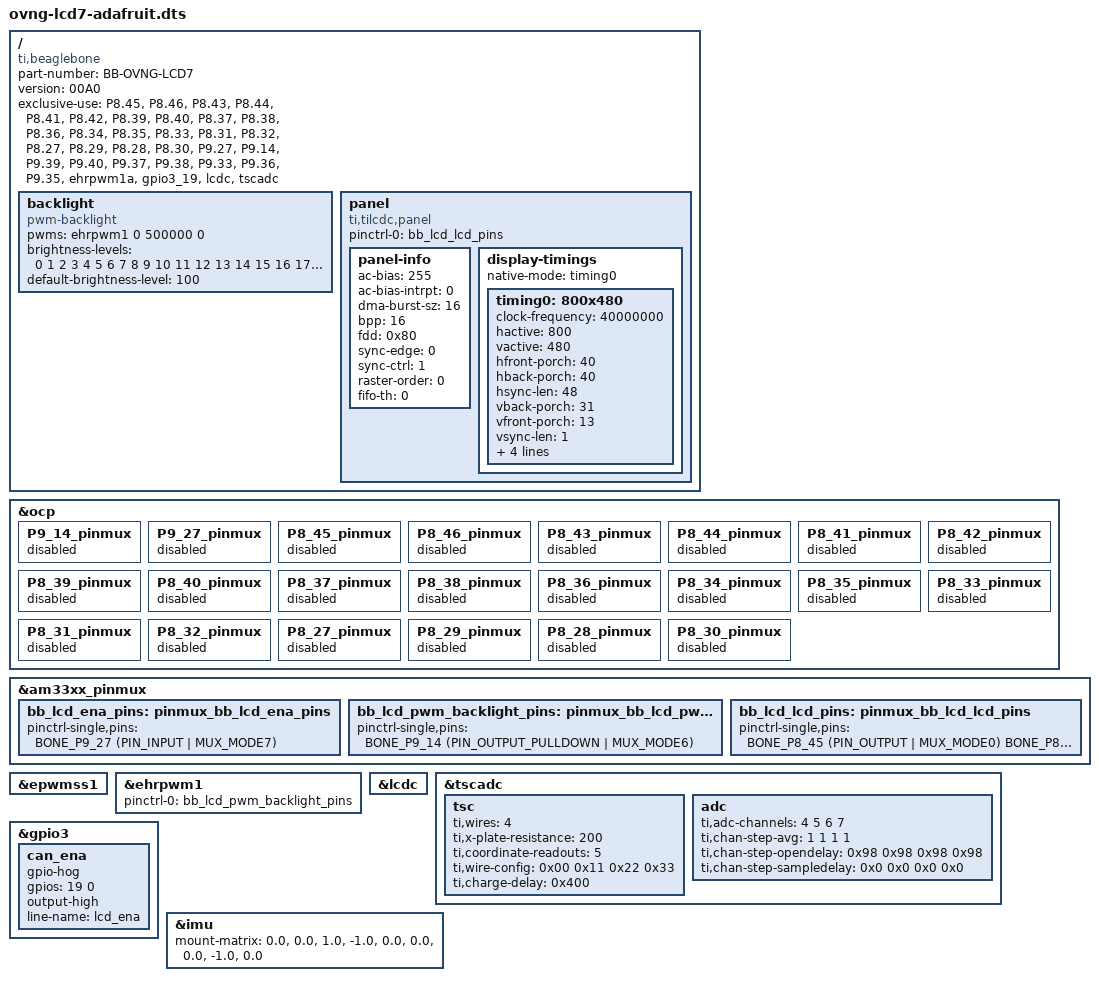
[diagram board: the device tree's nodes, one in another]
/*
 * Overlay for the Adafruit 2354 7.0"
 * 40-pin 800x480 TFT Display with Touchscreen
 *
 * https://www.adafruit.com/product/2354
 */

/dts-v1/;
/plugin/;

#include <dt-bindings/gpio/gpio.h>
#include <dt-bindings/pinctrl/am33xx.h>
#include <dt-bindings/board/am335x-bbw-bbb-base.h>

/ {
	compatible = "ti,beaglebone", "ti,beaglebone-black", "ti,beaglebone-green", "ti,beaglebone-green-wireless";

	/* identification */
	part-number = "BB-OVNG-LCD7";
	version = "00A0";

	/* state the resources this cape uses */
	exclusive-use =
		/* the pin header uses */
		"P8.45",	/* lcd: lcd_data0 */
		"P8.46",	/* lcd: lcd_data1 */
		"P8.43",	/* lcd: lcd_data2 */
		"P8.44",	/* lcd: lcd_data3 */
		"P8.41",	/* lcd: lcd_data4 */
		"P8.42",	/* lcd: lcd_data5 */
		"P8.39",	/* lcd: lcd_data6 */
		"P8.40",	/* lcd: lcd_data7 */
		"P8.37",	/* lcd: lcd_data8 */
		"P8.38",	/* lcd: lcd_data9 */
		"P8.36",	/* lcd: lcd_data10 */
		"P8.34",	/* lcd: lcd_data11 */
		"P8.35",	/* lcd: lcd_data12 */
		"P8.33",	/* lcd: lcd_data13 */
		"P8.31",	/* lcd: lcd_data14 */
		"P8.32",	/* lcd: lcd_data15 */
		"P8.27",	/* lcd: lcd_vsync */
		"P8.29",	/* lcd: lcd_hsync */
		"P8.28",	/* lcd: lcd_pclk */
		"P8.30",	/* lcd: lcd_ac_bias_en */
		"P9.27",	/* lcd: gpio3_19 DISPEN */
		"P9.14",	/* pwm: ehrpwm1a PWM_BL */
		"P9.39",	// AIN0
		"P9.40",	// AIN1
		"P9.37",	// AIN2
		"P9.38",	// AIN3
		"P9.33",	// AIN4
		"P9.36",	// AIN5
		"P9.35",	// AIN6

		"ehrpwm1a",
		"gpio3_19",	/* DISPEN */
		"lcdc",
		"tscadc";

	/*
	 * Free up the pins used by the cape from the pinmux helpers.
	 */
	fragment@0 {
		target = <&ocp>;
		__overlay__ {
			P9_14_pinmux { status = "disabled"; };	/* P9_14: gpmc_a2.ehrpwm1a */

			P9_27_pinmux { status = "disabled"; };	/* P9_27: mcasp0_fsr.gpio3_19 */

			P8_45_pinmux { status = "disabled"; };	/* P8_45: lcd_data0.lcd_data0 */
			P8_46_pinmux { status = "disabled"; };	/* P8_46: lcd_data1.lcd_data1 */
			P8_43_pinmux { status = "disabled"; };	/* P8_43: lcd_data2.lcd_data2 */
			P8_44_pinmux { status = "disabled"; };	/* P8_44: lcd_data3.lcd_data3 */
			P8_41_pinmux { status = "disabled"; };	/* P8_41: lcd_data4.lcd_data4 */
			P8_42_pinmux { status = "disabled"; };	/* P8_42: lcd_data5.lcd_data5 */
			P8_39_pinmux { status = "disabled"; };	/* P8_39: lcd_data6.lcd_data6 */
			P8_40_pinmux { status = "disabled"; };	/* P8_40: lcd_data7.lcd_data7 */
			P8_37_pinmux { status = "disabled"; };	/* P8_37: lcd_data8.lcd_data8 */
			P8_38_pinmux { status = "disabled"; };	/* P8_38: lcd_data9.lcd_data9 */
			P8_36_pinmux { status = "disabled"; };	/* P8_36: lcd_data10.lcd_data10 */
			P8_34_pinmux { status = "disabled"; };	/* P8_34: lcd_data11.lcd_data11 */
			P8_35_pinmux { status = "disabled"; };	/* P8_35: lcd_data12.lcd_data12 */
			P8_33_pinmux { status = "disabled"; };	/* P8_33: lcd_data13.lcd_data13 */
			P8_31_pinmux { status = "disabled"; };	/* P8_31: lcd_data14.lcd_data14 */
			P8_32_pinmux { status = "disabled"; };	/* P8_32: lcd_data15.lcd_data15 */

			P8_27_pinmux { status = "disabled"; };	/* P8_27: lcd_vsync.lcd_vsync */
			P8_29_pinmux { status = "disabled"; };	/* P8_29: lcd_hsync.lcd_hsync */
			P8_28_pinmux { status = "disabled"; };	/* P8_28: lcd_pclk.lcd_pclk */
			P8_30_pinmux { status = "disabled"; };	/* P8_30: lcd_ac_bias_en.lcd_ac_bias_en */
		};
	};

	fragment@1 {
		target = <&am33xx_pinmux>;
		__overlay__ {

			bb_lcd_ena_pins: pinmux_bb_lcd_ena_pins {
				pinctrl-single,pins = <
					BONE_P9_27 (PIN_INPUT | MUX_MODE7)	/* P9_27: mcasp0_fsr.gpio3_19 */
				>;
			};

			bb_lcd_pwm_backlight_pins: pinmux_bb_lcd_pwm_backlight_pins {
				pinctrl-single,pins = <
					BONE_P9_14 (PIN_OUTPUT_PULLDOWN | MUX_MODE6)	/* P9_14: gpmc_a2.ehrpwm1a */
				>;
			};

			bb_lcd_lcd_pins: pinmux_bb_lcd_lcd_pins {
				pinctrl-single,pins = <
					BONE_P8_45 (PIN_OUTPUT | MUX_MODE0)	/* P8_45: lcd_data0.lcd_data0 */
					BONE_P8_46 (PIN_OUTPUT | MUX_MODE0)	/* P8_46: lcd_data1.lcd_data1 */
					BONE_P8_43 (PIN_OUTPUT | MUX_MODE0)	/* P8_43: lcd_data2.lcd_data2 */
					BONE_P8_44 (PIN_OUTPUT | MUX_MODE0)	/* P8_44: lcd_data3.lcd_data3 */
					BONE_P8_41 (PIN_OUTPUT | MUX_MODE0)	/* P8_41: lcd_data4.lcd_data4 */
					BONE_P8_42 (PIN_OUTPUT | MUX_MODE0)	/* P8_42: lcd_data5.lcd_data5 */
					BONE_P8_39 (PIN_OUTPUT | MUX_MODE0)	/* P8_39: lcd_data6.lcd_data6 */
					BONE_P8_40 (PIN_OUTPUT | MUX_MODE0)	/* P8_40: lcd_data7.lcd_data7 */
					BONE_P8_37 (PIN_OUTPUT | MUX_MODE0)	/* P8_37: lcd_data8.lcd_data8 */
					BONE_P8_38 (PIN_OUTPUT | MUX_MODE0)	/* P8_38: lcd_data9.lcd_data9 */
					BONE_P8_36 (PIN_OUTPUT | MUX_MODE0)	/* P8_36: lcd_data10.lcd_data10 */
					BONE_P8_34 (PIN_OUTPUT | MUX_MODE0)	/* P8_34: lcd_data11.lcd_data11 */
					BONE_P8_35 (PIN_OUTPUT | MUX_MODE0)	/* P8_35: lcd_data12.lcd_data12 */
					BONE_P8_33 (PIN_OUTPUT | MUX_MODE0)	/* P8_33: lcd_data13.lcd_data13 */
					BONE_P8_31 (PIN_OUTPUT | MUX_MODE0)	/* P8_31: lcd_data14.lcd_data14 */
					BONE_P8_32 (PIN_OUTPUT | MUX_MODE0)	/* P8_32: lcd_data15.lcd_data15 */

					BONE_P8_27 (PIN_OUTPUT | MUX_MODE0)	/* P8_27: lcd_vsync.lcd_vsync */
					BONE_P8_29 (PIN_OUTPUT | MUX_MODE0)	/* P8_29: lcd_hsync.lcd_hsync */
					BONE_P8_28 (PIN_OUTPUT | MUX_MODE0)	/* P8_28: lcd_pclk.lcd_pclk */
					BONE_P8_30 (PIN_OUTPUT | MUX_MODE0)	/* P8_30: lcd_ac_bias_en.lcd_ac_bias_en */
				>;
			};

		};
	};

	fragment@2 {
		target = <&epwmss1>;
		__overlay__ {
			status = "okay";
		};
	};

	fragment@3 {
		target = <&ehrpwm1>;
		__overlay__ {
			pinctrl-names = "default";
			pinctrl-0 = <&bb_lcd_pwm_backlight_pins>;
			status = "okay";
		};
	};

	fragment@4 {
		target = <&lcdc>;
		__overlay__ {
			status = "okay";
		};
	};

	fragment@5 {
		target = <&tscadc>;
		__overlay__ {
			status = "okay";

			tsc {
				ti,wires = <4>;
				ti,x-plate-resistance = <200>;
				ti,coordinate-readouts = <5>;
				ti,wire-config = <0x00 0x11 0x22 0x33>;
				ti,charge-delay = <0x400>;
			};

			adc {
				ti,adc-channels = <4 5 6 7>;
				ti,chan-step-avg = <1 1 1 1>;
				ti,chan-step-opendelay = <0x98 0x98 0x98 0x98>;
				ti,chan-step-sampledelay = <0x0 0x0 0x0 0x0>;
			};
		};
	};

	fragment@6 {
		target-path="/";
		__overlay__ {
			backlight {
				status = "okay";
				compatible = "pwm-backlight";
				pwms = <&ehrpwm1 0 500000 0>;
				brightness-levels = <
					0  1  2  3  4  5  6  7  8  9
					10 11 12 13 14 15 16 17 18 19
					20 21 22 23 24 25 26 27 28 29
					30 31 32 33 34 35 36 37 38 39
					40 41 42 43 44 45 46 47 48 49
					50 51 52 53 54 55 56 57 58 59
					60 61 62 63 64 65 66 67 68 69
					70 71 72 73 74 75 76 77 78 79
					80 81 82 83 84 85 86 87 88 89
					90 91 92 93 94 95 96 97 98 99
					100
				>;
				default-brightness-level = <100>;
			};

			panel {
				status = "okay";
				compatible = "ti,tilcdc,panel";
				pinctrl-names = "default";
				pinctrl-0 = <&bb_lcd_lcd_pins>;
				panel-info {
					ac-bias           = <255>;
					ac-bias-intrpt    = <0>;
					dma-burst-sz      = <16>;
					bpp               = <16>;
					fdd               = <0x80>;
					sync-edge         = <0>;
					sync-ctrl         = <1>;
					raster-order      = <0>;
					fifo-th           = <0>;
				};
				display-timings {
					native-mode = <&timing0>;
					timing0: 800x480 {
						clock-frequency = <40000000>;
						hactive = <800>;
						vactive = <480>;
						hfront-porch = <40>;
						hback-porch = <40>;
						hsync-len = <48>;
						vback-porch = <31>;
						vfront-porch = <13>;
						vsync-len = <1>;
						hsync-active = <0>;
						vsync-active = <0>;
						de-active = <1>;
						pixelclk-active = <0>;
					};
				};
			};
		};
	};

	fragment@7 {
		target = <&gpio3>;
		__overlay__ {
			can_ena {
				gpio-hog;
				gpios = <19 0>;
				output-high;
				line-name = "lcd_ena";
			};
		};
	};

	fragment@8 {
		target = <&imu>;
		__overlay__ {
			mount-matrix =
				"0.0", "0.0", "1.0",
				"-1.0", "0.0", "0.0",
				"0.0", "-1.0", "0.0";
		};
	};
};
